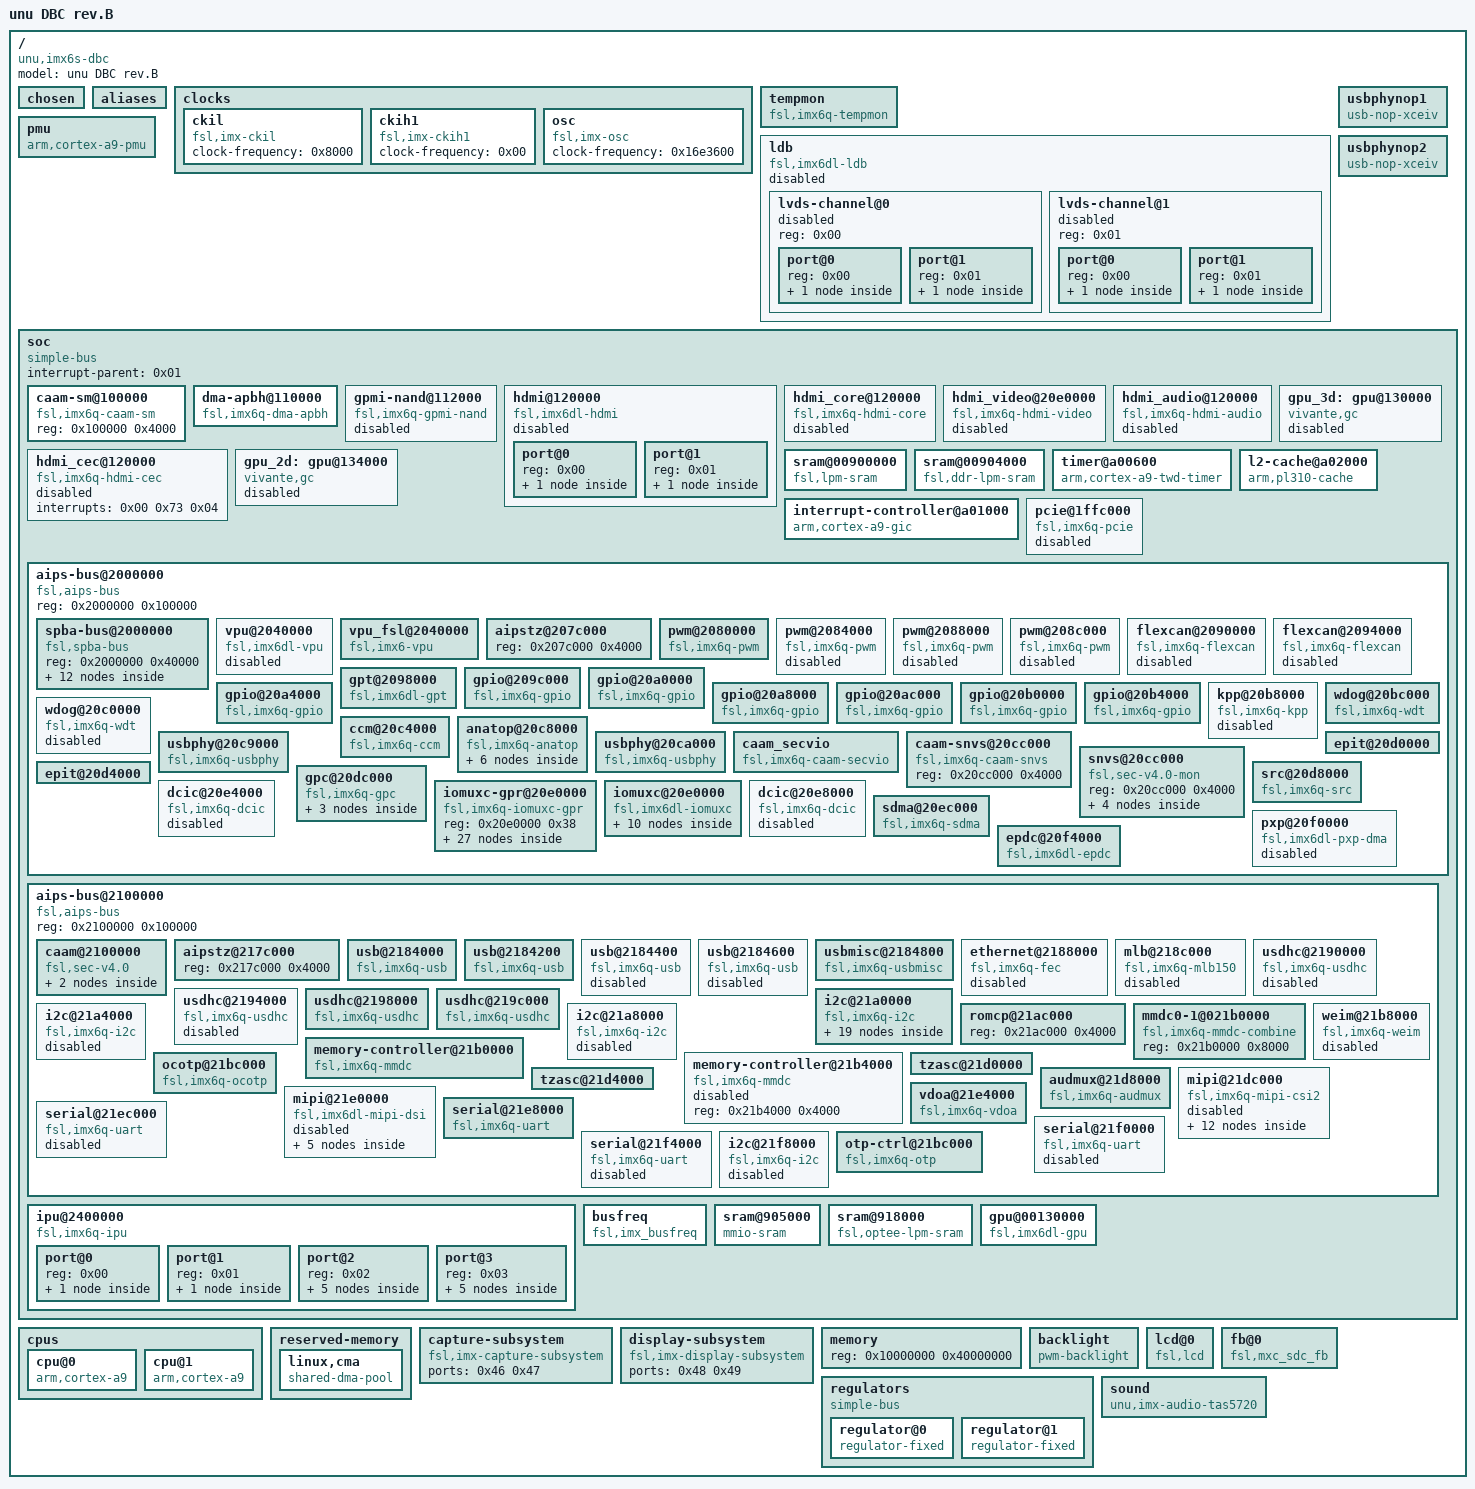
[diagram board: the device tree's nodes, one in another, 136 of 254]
/dts-v1/;

/ {
	#address-cells = <0x01>;
	#size-cells = <0x01>;
	model = "unu DBC rev.B";
	compatible = "unu,imx6s-dbc\0fsl,imx6dl";

	chosen {
	};

	aliases {
		ethernet0 = "/soc/aips-bus@2100000/ethernet@2188000";
		can0 = "/soc/aips-bus@2000000/flexcan@2090000";
		can1 = "/soc/aips-bus@2000000/flexcan@2094000";
		gpio0 = "/soc/aips-bus@2000000/gpio@209c000";
		gpio1 = "/soc/aips-bus@2000000/gpio@20a0000";
		gpio2 = "/soc/aips-bus@2000000/gpio@20a4000";
		gpio3 = "/soc/aips-bus@2000000/gpio@20a8000";
		gpio4 = "/soc/aips-bus@2000000/gpio@20ac000";
		gpio5 = "/soc/aips-bus@2000000/gpio@20b0000";
		gpio6 = "/soc/aips-bus@2000000/gpio@20b4000";
		i2c0 = "/soc/aips-bus@2100000/i2c@21a0000";
		i2c1 = "/soc/aips-bus@2100000/i2c@21a4000";
		i2c2 = "/soc/aips-bus@2100000/i2c@21a8000";
		ipu0 = "/soc/ipu@2400000";
		mmc0 = "/soc/aips-bus@2100000/usdhc@2190000";
		mmc1 = "/soc/aips-bus@2100000/usdhc@2194000";
		mmc2 = "/soc/aips-bus@2100000/usdhc@2198000";
		mmc3 = "/soc/aips-bus@2100000/usdhc@219c000";
		serial0 = "/soc/aips-bus@2000000/spba-bus@2000000/serial@2020000";
		serial1 = "/soc/aips-bus@2100000/serial@21e8000";
		serial2 = "/soc/aips-bus@2100000/serial@21ec000";
		serial3 = "/soc/aips-bus@2100000/serial@21f0000";
		serial4 = "/soc/aips-bus@2100000/serial@21f4000";
		spi0 = "/soc/aips-bus@2000000/spba-bus@2000000/spi@2008000";
		spi1 = "/soc/aips-bus@2000000/spba-bus@2000000/spi@200c000";
		spi2 = "/soc/aips-bus@2000000/spba-bus@2000000/spi@2010000";
		spi3 = "/soc/aips-bus@2000000/spba-bus@2000000/spi@2014000";
		usbphy0 = "/soc/aips-bus@2000000/usbphy@20c9000";
		usbphy1 = "/soc/aips-bus@2000000/usbphy@20ca000";
		i2c3 = "/soc/aips-bus@2100000/i2c@21f8000";
		mxcfb0 = "/fb@0";
	};

	clocks {

		ckil {
			compatible = "fsl,imx-ckil\0fixed-clock";
			#clock-cells = <0x00>;
			clock-frequency = <0x8000>;
		};

		ckih1 {
			compatible = "fsl,imx-ckih1\0fixed-clock";
			#clock-cells = <0x00>;
			clock-frequency = <0x00>;
		};

		osc {
			compatible = "fsl,imx-osc\0fixed-clock";
			#clock-cells = <0x00>;
			clock-frequency = <0x16e3600>;
		};
	};

	tempmon {
		compatible = "fsl,imx6q-tempmon";
		interrupt-parent = <0x01>;
		interrupts = <0x00 0x31 0x04>;
		fsl,tempmon = <0x02>;
		fsl,tempmon-data = <0x03>;
		clocks = <0x04 0xac>;
		#thermal-sensor-cells = <0x00>;
	};

	ldb {
		#address-cells = <0x01>;
		#size-cells = <0x00>;
		compatible = "fsl,imx6dl-ldb\0fsl,imx53-ldb";
		gpr = <0x05>;
		status = "disabled";
		clocks = <0x04 0x87 0x04 0x88 0x04 0x27 0x04 0x28 0x04 0x29 0x04 0xb8 0x04 0xb9 0x04 0x10b 0x04 0x10c 0x04 0x10d 0x04 0x10e>;
		clock-names = "ldb_di0\0ldb_di1\0di0_sel\0di1_sel\0di2_sel\0ldb_di0_div_3_5\0ldb_di1_div_3_5\0ldb_di0_div_7\0ldb_di1_div_7\0ldb_di0_div_sel\0ldb_di1_div_sel";

		lvds-channel@0 {
			#address-cells = <0x01>;
			#size-cells = <0x00>;
			reg = <0x00>;
			status = "disabled";

			port@0 {
				reg = <0x00>;

				endpoint {
					remote-endpoint = <0x06>;
					phandle = <0x3d>;
				};
			};

			port@1 {
				reg = <0x01>;

				endpoint {
					remote-endpoint = <0x07>;
					phandle = <0x41>;
				};
			};
		};

		lvds-channel@1 {
			#address-cells = <0x01>;
			#size-cells = <0x00>;
			reg = <0x01>;
			status = "disabled";

			port@0 {
				reg = <0x00>;

				endpoint {
					remote-endpoint = <0x08>;
					phandle = <0x3e>;
				};
			};

			port@1 {
				reg = <0x01>;

				endpoint {
					remote-endpoint = <0x09>;
					phandle = <0x42>;
				};
			};
		};
	};

	pmu {
		compatible = "arm,cortex-a9-pmu";
		interrupt-parent = <0x01>;
		interrupts = <0x00 0x5e 0x04>;
	};

	usbphynop1 {
		compatible = "usb-nop-xceiv";
		#phy-cells = <0x00>;
		phandle = <0x26>;
	};

	usbphynop2 {
		compatible = "usb-nop-xceiv";
		#phy-cells = <0x00>;
		phandle = <0x27>;
	};

	soc {
		#address-cells = <0x01>;
		#size-cells = <0x01>;
		compatible = "simple-bus";
		interrupt-parent = <0x01>;
		ranges;

		caam-sm@100000 {
			compatible = "fsl,imx6q-caam-sm";
			reg = <0x100000 0x4000>;
		};

		dma-apbh@110000 {
			compatible = "fsl,imx6q-dma-apbh\0fsl,imx28-dma-apbh";
			reg = <0x110000 0x2000>;
			interrupts = <0x00 0x0d 0x04 0x00 0x0d 0x04 0x00 0x0d 0x04 0x00 0x0d 0x04>;
			interrupt-names = "gpmi0\0gpmi1\0gpmi2\0gpmi3";
			#dma-cells = <0x01>;
			dma-channels = <0x04>;
			clocks = <0x04 0x6a>;
			phandle = <0x0a>;
		};

		gpmi-nand@112000 {
			compatible = "fsl,imx6q-gpmi-nand";
			reg = <0x112000 0x2000 0x114000 0x2000>;
			reg-names = "gpmi-nand\0bch";
			interrupts = <0x00 0x0f 0x04>;
			interrupt-names = "bch";
			clocks = <0x04 0x98 0x04 0x99 0x04 0x97 0x04 0x96 0x04 0x95>;
			clock-names = "gpmi_io\0gpmi_apb\0gpmi_bch\0gpmi_bch_apb\0per1_bch";
			dmas = <0x0a 0x00>;
			dma-names = "rx-tx";
			status = "disabled";
		};

		hdmi@120000 {
			#address-cells = <0x01>;
			#size-cells = <0x00>;
			reg = <0x120000 0x9000>;
			interrupts = <0x00 0x73 0x04>;
			gpr = <0x05>;
			clocks = <0x04 0x7b 0x04 0x7c>;
			clock-names = "iahb\0isfr";
			status = "disabled";
			compatible = "fsl,imx6dl-hdmi";

			port@0 {
				reg = <0x00>;

				endpoint {
					remote-endpoint = <0x0b>;
					phandle = <0x3b>;
				};
			};

			port@1 {
				reg = <0x01>;

				endpoint {
					remote-endpoint = <0x0c>;
					phandle = <0x3f>;
				};
			};
		};

		hdmi_core@120000 {
			compatible = "fsl,imx6q-hdmi-core";
			reg = <0x120000 0x9000>;
			clocks = <0x04 0x7c 0x04 0x7b 0x04 0x8a>;
			clock-names = "hdmi_isfr\0hdmi_iahb\0mipi_core";
			status = "disabled";
		};

		hdmi_video@20e0000 {
			compatible = "fsl,imx6q-hdmi-video";
			reg = <0x20e0000 0x1000>;
			reg-names = "hdmi_gpr";
			interrupts = <0x00 0x73 0x04>;
			clocks = <0x04 0x7c 0x04 0x7b 0x04 0x8a>;
			clock-names = "hdmi_isfr\0hdmi_iahb\0mipi_core";
			status = "disabled";
		};

		hdmi_audio@120000 {
			compatible = "fsl,imx6q-hdmi-audio";
			clocks = <0x04 0x7c 0x04 0x7b 0x04 0x8a>;
			clock-names = "hdmi_isfr\0hdmi_iahb\0mipi_core";
			dmas = <0x0d 0x02 0x1a 0x00>;
			dma-names = "tx";
			status = "disabled";
		};

		hdmi_cec@120000 {
			compatible = "fsl,imx6q-hdmi-cec";
			interrupts = <0x00 0x73 0x04>;
			status = "disabled";
		};

		gpu_3d: gpu@130000 {
			compatible = "vivante,gc";
			reg = <0x130000 0x4000>;
			interrupts = <0x00 0x09 0x04>;
			clocks = <0x04 0x1b 0x04 0x7a 0x04 0x4a>;
			clock-names = "bus\0core\0shader";
			power-domains = <0x0e>;
			#cooling-cells = <0x02>;
			status = "disabled";
		};

		gpu_2d: gpu@134000 {
			compatible = "vivante,gc";
			reg = <0x134000 0x4000>;
			interrupts = <0x00 0x0a 0x04>;
			clocks = <0x04 0x1a 0x04 0x79>;
			clock-names = "bus\0core";
			power-domains = <0x0e>;
			#cooling-cells = <0x02>;
			status = "disabled";
		};

		sram@00900000 {
			compatible = "fsl,lpm-sram";
			reg = <0x900000 0x4000>;
			clocks = <0x04 0x8e>;
		};

		sram@00904000 {
			compatible = "fsl,ddr-lpm-sram";
			reg = <0x904000 0x1000>;
			clocks = <0x04 0x8e>;
		};

		timer@a00600 {
			compatible = "arm,cortex-a9-twd-timer";
			reg = <0xa00600 0x20>;
			interrupts = <0x01 0x0d 0xf01>;
			interrupt-parent = <0x0f>;
			clocks = <0x04 0x0f>;
		};

		interrupt-controller@a01000 {
			compatible = "arm,cortex-a9-gic";
			#interrupt-cells = <0x03>;
			interrupt-controller;
			reg = <0xa01000 0x1000 0xa00100 0x100>;
			interrupt-parent = <0x0f>;
			phandle = <0x0f>;
		};

		l2-cache@a02000 {
			compatible = "arm,pl310-cache";
			reg = <0xa02000 0x1000>;
			interrupts = <0x00 0x5c 0x04>;
			cache-unified;
			cache-level = <0x02>;
			arm,tag-latency = <0x04 0x02 0x03>;
			arm,data-latency = <0x04 0x02 0x03>;
			arm,shared-override;
			phandle = <0x43>;
		};

		pcie@1ffc000 {
			compatible = "fsl,imx6q-pcie\0snps,dw-pcie";
			reg = <0x1ffc000 0x4000 0x1f00000 0x80000>;
			reg-names = "dbi\0config";
			#address-cells = <0x03>;
			#size-cells = <0x02>;
			device_type = "pci";
			bus-range = <0x00 0xff>;
			ranges = <0x81000000 0x00 0x00 0x1f80000 0x00 0x10000 0x82000000 0x00 0x1000000 0x1000000 0x00 0xf00000>;
			num-lanes = <0x01>;
			num-viewport = <0x04>;
			interrupts = <0x00 0x78 0x04>;
			interrupt-names = "msi";
			#interrupt-cells = <0x01>;
			interrupt-map-mask = <0x00 0x00 0x00 0x07>;
			interrupt-map = <0x00 0x00 0x00 0x01 0x01 0x00 0x7b 0x04 0x00 0x00 0x00 0x02 0x01 0x00 0x7a 0x04 0x00 0x00 0x00 0x03 0x01 0x00 0x79 0x04 0x00 0x00 0x00 0x04 0x01 0x00 0x78 0x04>;
			clocks = <0x04 0x90 0x04 0xce 0x04 0xbd>;
			clock-names = "pcie\0pcie_bus\0pcie_phy";
			status = "disabled";
		};

		aips-bus@2000000 {
			compatible = "fsl,aips-bus\0simple-bus";
			#address-cells = <0x01>;
			#size-cells = <0x01>;
			reg = <0x2000000 0x100000>;
			ranges;

			spba-bus@2000000 {
				compatible = "fsl,spba-bus\0simple-bus";
				#address-cells = <0x01>;
				#size-cells = <0x01>;
				reg = <0x2000000 0x40000>;
				ranges;

				spdif@2004000 {
					compatible = "fsl,imx35-spdif";
					reg = <0x2004000 0x4000>;
					interrupts = <0x00 0x34 0x04>;
					dmas = <0x0d 0x0e 0x12 0x00 0x0d 0x0f 0x12 0x00>;
					dma-names = "rx\0tx";
					clocks = <0x04 0xf4 0x04 0x03 0x04 0xc5 0x04 0x6b 0x04 0x00 0x04 0x76 0x04 0x3e 0x04 0x8b 0x04 0x00 0x04 0x9c>;
					clock-names = "core\0rxtx0\0rxtx1\0rxtx2\0rxtx3\0rxtx4\0rxtx5\0rxtx6\0rxtx7\0spba";
					status = "disabled";
				};

				spi@2008000 {
					#address-cells = <0x01>;
					#size-cells = <0x00>;
					compatible = "fsl,imx6q-ecspi\0fsl,imx51-ecspi";
					reg = <0x2008000 0x4000>;
					interrupts = <0x00 0x1f 0x04>;
					clocks = <0x04 0x70 0x04 0x70>;
					clock-names = "ipg\0per";
					dmas = <0x0d 0x03 0x07 0x01 0x0d 0x04 0x07 0x02>;
					dma-names = "rx\0tx";
					status = "disabled";
				};

				spi@200c000 {
					#address-cells = <0x01>;
					#size-cells = <0x00>;
					compatible = "fsl,imx6q-ecspi\0fsl,imx51-ecspi";
					reg = <0x200c000 0x4000>;
					interrupts = <0x00 0x20 0x04>;
					clocks = <0x04 0x71 0x04 0x71>;
					clock-names = "ipg\0per";
					dmas = <0x0d 0x05 0x07 0x01 0x0d 0x06 0x07 0x02>;
					dma-names = "rx\0tx";
					status = "disabled";
				};

				spi@2010000 {
					#address-cells = <0x01>;
					#size-cells = <0x00>;
					compatible = "fsl,imx6q-ecspi\0fsl,imx51-ecspi";
					reg = <0x2010000 0x4000>;
					interrupts = <0x00 0x21 0x04>;
					clocks = <0x04 0x72 0x04 0x72>;
					clock-names = "ipg\0per";
					dmas = <0x0d 0x07 0x07 0x01 0x0d 0x08 0x07 0x02>;
					dma-names = "rx\0tx";
					status = "disabled";
				};

				spi@2014000 {
					#address-cells = <0x01>;
					#size-cells = <0x00>;
					compatible = "fsl,imx6q-ecspi\0fsl,imx51-ecspi";
					reg = <0x2014000 0x4000>;
					interrupts = <0x00 0x22 0x04>;
					clocks = <0x04 0x73 0x04 0x73>;
					clock-names = "ipg\0per";
					dmas = <0x0d 0x09 0x07 0x01 0x0d 0x0a 0x07 0x02>;
					dma-names = "rx\0tx";
					status = "disabled";
				};

				serial@2020000 {
					compatible = "fsl,imx6q-uart\0fsl,imx21-uart";
					reg = <0x2020000 0x4000>;
					interrupts = <0x00 0x1a 0x04>;
					clocks = <0x04 0xa0 0x04 0xa1>;
					clock-names = "ipg\0per";
					dmas = <0x0d 0x19 0x04 0x00 0x0d 0x1a 0x04 0x00>;
					dma-names = "rx\0tx";
					status = "okay";
					pinctrl-names = "default";
					pinctrl-0 = <0x10>;
				};

				esai@2024000 {
					#sound-dai-cells = <0x00>;
					compatible = "fsl,imx35-esai";
					reg = <0x2024000 0x4000>;
					interrupts = <0x00 0x33 0x04>;
					clocks = <0x04 0xd0 0x04 0xd1 0x04 0x76 0x04 0xd0 0x04 0x9c>;
					clock-names = "core\0mem\0extal\0fsys\0spba";
					dmas = <0x0d 0x17 0x15 0x00 0x0d 0x18 0x15 0x00>;
					dma-names = "rx\0tx";
					status = "disabled";
				};

				ssi@2028000 {
					#sound-dai-cells = <0x00>;
					compatible = "fsl,imx6q-ssi\0fsl,imx51-ssi";
					reg = <0x2028000 0x4000>;
					interrupts = <0x00 0x2e 0x04>;
					clocks = <0x04 0xb2 0x04 0x9d>;
					clock-names = "ipg\0baud";
					dmas = <0x0d 0x25 0x01 0x00 0x0d 0x26 0x01 0x00>;
					dma-names = "rx\0tx";
					fsl,fifo-depth = <0x0f>;
					status = "okay";
					assigned-clocks = <0x04 0x2d 0x04 0x9d>;
					assigned-clock-parents = <0x04 0xcb>;
					assigned-clock-rates = <0x00 0xbb8000>;
					phandle = <0x4c>;
				};

				ssi@202c000 {
					#sound-dai-cells = <0x00>;
					compatible = "fsl,imx6q-ssi\0fsl,imx51-ssi";
					reg = <0x202c000 0x4000>;
					interrupts = <0x00 0x2f 0x04>;
					clocks = <0x04 0xb3 0x04 0x9e>;
					clock-names = "ipg\0baud";
					dmas = <0x0d 0x29 0x01 0x00 0x0d 0x2a 0x01 0x00>;
					dma-names = "rx\0tx";
					fsl,fifo-depth = <0x0f>;
					status = "disabled";
				};

				ssi@2030000 {
					#sound-dai-cells = <0x00>;
					compatible = "fsl,imx6q-ssi\0fsl,imx51-ssi";
					reg = <0x2030000 0x4000>;
					interrupts = <0x00 0x30 0x04>;
					clocks = <0x04 0xb4 0x04 0x9f>;
					clock-names = "ipg\0baud";
					dmas = <0x0d 0x2d 0x01 0x00 0x0d 0x2e 0x01 0x00>;
					dma-names = "rx\0tx";
					fsl,fifo-depth = <0x0f>;
					status = "disabled";
				};

				asrc@2034000 {
					compatible = "fsl,imx53-asrc";
					reg = <0x2034000 0x4000>;
					interrupts = <0x00 0x32 0x04>;
					clocks = <0x04 0xd2 0x04 0xd3 0x04 0x00 0x04 0x00 0x04 0x00 0x04 0x00 0x04 0x00 0x04 0x00 0x04 0x00 0x04 0x00 0x04 0x00 0x04 0x00 0x04 0x00 0x04 0x00 0x04 0x00 0x04 0x6b 0x04 0x00 0x04 0x00 0x04 0x9c>;
					clock-names = "mem\0ipg\0asrck_0\0asrck_1\0asrck_2\0asrck_3\0asrck_4\0asrck_5\0asrck_6\0asrck_7\0asrck_8\0asrck_9\0asrck_a\0asrck_b\0asrck_c\0asrck_d\0asrck_e\0asrck_f\0spba";
					dmas = <0x0d 0x11 0x17 0x01 0x0d 0x12 0x17 0x01 0x0d 0x13 0x17 0x01 0x0d 0x14 0x17 0x01 0x0d 0x15 0x17 0x01 0x0d 0x16 0x17 0x01>;
					dma-names = "rxa\0rxb\0rxc\0txa\0txb\0txc";
					fsl,asrc-rate = <0xbb80>;
					fsl,asrc-width = <0x10>;
					status = "okay";
				};

				spba@203c000 {
					reg = <0x203c000 0x4000>;
				};
			};

			vpu@2040000 {
				compatible = "fsl,imx6dl-vpu\0cnm,coda960";
				reg = <0x2040000 0x3c000>;
				interrupts = <0x00 0x0c 0x04 0x00 0x03 0x04>;
				interrupt-names = "bit\0jpeg";
				clocks = <0x04 0xa8 0x04 0x8c>;
				clock-names = "per\0ahb";
				power-domains = <0x0e>;
				resets = <0x11 0x01>;
				iram = <0x12>;
				status = "disabled";
			};

			vpu_fsl@2040000 {
				compatible = "fsl,imx6-vpu";
				reg = <0x2040000 0x3c000>;
				reg-names = "vpu_regs";
				interrupts = <0x00 0x03 0x04 0x00 0x0c 0x04>;
				interrupt-names = "vpu_jpu_irq\0vpu_ipi_irq";
				clocks = <0x04 0xa8 0x04 0x8c 0x04 0x8e>;
				clock-names = "vpu_clk\0mmdc_ch0_axi\0ocram";
				iramsize = <0x00>;
				iram = <0x12>;
				resets = <0x11 0x01>;
				power-domains = <0x0e>;
			};

			aipstz@207c000 {
				reg = <0x207c000 0x4000>;
			};

			pwm@2080000 {
				#pwm-cells = <0x02>;
				compatible = "fsl,imx6q-pwm\0fsl,imx27-pwm";
				reg = <0x2080000 0x4000>;
				interrupts = <0x00 0x53 0x04>;
				clocks = <0x04 0x3e 0x04 0x91>;
				clock-names = "ipg\0per";
				status = "okay";
				pinctrl-names = "default";
				pinctrl-0 = <0x13>;
				phandle = <0x4a>;
			};

			pwm@2084000 {
				#pwm-cells = <0x02>;
				compatible = "fsl,imx6q-pwm\0fsl,imx27-pwm";
				reg = <0x2084000 0x4000>;
				interrupts = <0x00 0x54 0x04>;
				clocks = <0x04 0x3e 0x04 0x92>;
				clock-names = "ipg\0per";
				status = "disabled";
			};

			pwm@2088000 {
				#pwm-cells = <0x02>;
				compatible = "fsl,imx6q-pwm\0fsl,imx27-pwm";
				reg = <0x2088000 0x4000>;
				interrupts = <0x00 0x55 0x04>;
				clocks = <0x04 0x3e 0x04 0x93>;
				clock-names = "ipg\0per";
				status = "disabled";
			};

			pwm@208c000 {
				#pwm-cells = <0x02>;
				compatible = "fsl,imx6q-pwm\0fsl,imx27-pwm";
				reg = <0x208c000 0x4000>;
				interrupts = <0x00 0x56 0x04>;
				clocks = <0x04 0x3e 0x04 0x94>;
				clock-names = "ipg\0per";
				status = "disabled";
			};

			flexcan@2090000 {
				compatible = "fsl,imx6q-flexcan";
				reg = <0x2090000 0x4000>;
				interrupts = <0x00 0x6e 0x04>;
				clocks = <0x04 0x6c 0x04 0x6d>;
				clock-names = "ipg\0per";
				fsl,stop-mode = <0x05 0x34 0x1c 0x10 0x11>;
				status = "disabled";
			};

			flexcan@2094000 {
				compatible = "fsl,imx6q-flexcan";
				reg = <0x2094000 0x4000>;
				interrupts = <0x00 0x6f 0x04>;
				clocks = <0x04 0x6e 0x04 0x6f>;
				clock-names = "ipg\0per";
				fsl,stop-mode = <0x05 0x34 0x1d 0x10 0x12>;
				status = "disabled";
			};

			gpt@2098000 {
				compatible = "fsl,imx6dl-gpt";
				reg = <0x2098000 0x4000>;
				interrupts = <0x00 0x37 0x04>;
				clocks = <0x04 0x77 0x04 0x78 0x04 0xed>;
				clock-names = "ipg\0per\0osc_per";
			};

			gpio@209c000 {
				compatible = "fsl,imx6q-gpio\0fsl,imx35-gpio";
				reg = <0x209c000 0x4000>;
				interrupts = <0x00 0x42 0x04 0x00 0x43 0x04>;
				gpio-controller;
				#gpio-cells = <0x02>;
				interrupt-controller;
				#interrupt-cells = <0x02>;
				gpio-ranges = <0x14 0x00 0x83 0x02 0x14 0x02 0x89 0x08 0x14 0x0a 0xbd 0x02 0x14 0x0c 0xc2 0x01 0x14 0x0d 0xc1 0x01 0x14 0x0e 0xc0 0x01 0x14 0x0f 0xbf 0x01 0x14 0x10 0xb9 0x02 0x14 0x12 0xb8 0x01 0x14 0x13 0xbb 0x01 0x14 0x14 0xb7 0x01 0x14 0x15 0xbc 0x01 0x14 0x16 0x7b 0x03 0x14 0x19 0x79 0x01 0x14 0x1a 0x7f 0x01 0x14 0x1b 0x7e 0x01 0x14 0x1c 0x80 0x01 0x14 0x1d 0x82 0x01 0x14 0x1e 0x81 0x01 0x14 0x1f 0x7a 0x01>;
			};

			gpio@20a0000 {
				compatible = "fsl,imx6q-gpio\0fsl,imx35-gpio";
				reg = <0x20a0000 0x4000>;
				interrupts = <0x00 0x44 0x04 0x00 0x45 0x04>;
				gpio-controller;
				#gpio-cells = <0x02>;
				interrupt-controller;
				#interrupt-cells = <0x02>;
				gpio-ranges = <0x14 0x00 0xa1 0x08 0x14 0x08 0xd0 0x08 0x14 0x10 0x4a 0x01 0x14 0x11 0x49 0x01 0x14 0x12 0x48 0x01 0x14 0x13 0x47 0x01 0x14 0x14 0x46 0x01 0x14 0x15 0x45 0x01 0x14 0x16 0x44 0x01 0x14 0x17 0x4f 0x02 0x14 0x19 0x76 0x02 0x14 0x1b 0x75 0x01 0x14 0x1c 0x71 0x04>;
			};

			gpio@20a4000 {
				compatible = "fsl,imx6q-gpio\0fsl,imx35-gpio";
				reg = <0x20a4000 0x4000>;
				interrupts = <0x00 0x46 0x04 0x00 0x47 0x04>;
				gpio-controller;
				#gpio-cells = <0x02>;
				interrupt-controller;
				#interrupt-cells = <0x02>;
				gpio-ranges = <0x14 0x00 0x61 0x02 0x14 0x02 0x69 0x08 0x14 0x0a 0x63 0x06 0x14 0x10 0x51 0x10>;
			};

			gpio@20a8000 {
				compatible = "fsl,imx6q-gpio\0fsl,imx35-gpio";
				reg = <0x20a8000 0x4000>;
				interrupts = <0x00 0x48 0x04 0x00 0x49 0x04>;
				gpio-controller;
				#gpio-cells = <0x02>;
				interrupt-controller;
				#interrupt-cells = <0x02>;
				gpio-ranges = <0x14 0x05 0x88 0x01 0x14 0x06 0x91 0x01 0x14 0x07 0x96 0x01 0x14 0x08 0x92 0x01 0x14 0x09 0x97 0x01 0x14 0x0a 0x93 0x01 0x14 0x0b 0x98 0x01 0x14 0x0c 0x94 0x01 0x14 0x0d 0x99 0x01 0x14 0x0e 0x95 0x01 0x14 0x0f 0x9a 0x01 0x14 0x10 0x27 0x07 0x14 0x17 0x38 0x01 0x14 0x18 0x3d 0x07 0x14 0x1f 0x2e 0x01>;
			};

			gpio@20ac000 {
				compatible = "fsl,imx6q-gpio\0fsl,imx35-gpio";
				reg = <0x20ac000 0x4000>;
				interrupts = <0x00 0x4a 0x04 0x00 0x4b 0x04>;
				gpio-controller;
				#gpio-cells = <0x02>;
				interrupt-controller;
				#interrupt-cells = <0x02>;
				gpio-ranges = <0x14 0x00 0x78 0x01 0x14 0x02 0x4d 0x01 0x14 0x04 0x4c 0x01 0x14 0x05 0x2f 0x09 0x14 0x0e 0x39 0x04 0x14 0x12 0x25 0x01 0x14 0x13 0x24 0x01 0x14 0x14 0x23 0x01 0x14 0x15 0x26 0x01 0x14 0x16 0x1d 0x06 0x14 0x1c 0x13 0x04>;
			};

			gpio@20b0000 {
				compatible = "fsl,imx6q-gpio\0fsl,imx35-gpio";
				reg = <0x20b0000 0x4000>;
				interrupts = <0x00 0x4c 0x04 0x00 0x4d 0x04>;
				gpio-controller;
				#gpio-cells = <0x02>;
				interrupt-controller;
				#interrupt-cells = <0x02>;
				gpio-ranges = <0x14 0x00 0x17 0x06 0x14 0x06 0x4b 0x01 0x14 0x07 0x9c 0x01 0x14 0x08 0x9b 0x01 0x14 0x09 0xaa 0x01 0x14 0x0a 0xa9 0x01 0x14 0x0b 0x9d 0x01 0x14 0x0e 0x9e 0x03 0x14 0x11 0xcc 0x01 0x14 0x12 0xcb 0x01 0x14 0x13 0xb6 0x01 0x14 0x14 0xb1 0x04 0x14 0x18 0xaf 0x01 0x14 0x19 0xab 0x01 0x14 0x1a 0xb5 0x01 0x14 0x1b 0xac 0x03 0x14 0x1e 0xb0 0x01 0x14 0x1f 0x4e 0x01>;
			};

			gpio@20b4000 {
				compatible = "fsl,imx6q-gpio\0fsl,imx35-gpio";
				reg = <0x20b4000 0x4000>;
				interrupts = <0x00 0x4e 0x04 0x00 0x4f 0x04>;
				gpio-controller;
				#gpio-cells = <0x02>;
				interrupt-controller;
				#interrupt-cells = <0x02>;
				gpio-ranges = <0x14 0x00 0xca 0x01 0x14 0x01 0xc9 0x01 0x14 0x02 0xc4 0x01 0x14 0x03 0xc3 0x01 0x14 0x04 0xc5 0x04 0x14 0x08 0xcd 0x01 0x14 0x09 0xcf 0x01 0x14 0x0a 0xce 0x01 0x14 0x0b 0x85 0x03>;
			};

			kpp@20b8000 {
				compatible = "fsl,imx6q-kpp\0fsl,imx21-kpp";
				reg = <0x20b8000 0x4000>;
				interrupts = <0x00 0x52 0x04>;
				clocks = <0x04 0x3e>;
				status = "disabled";
			};

			wdog@20bc000 {
				compatible = "fsl,imx6q-wdt\0fsl,imx21-wdt";
				reg = <0x20bc000 0x4000>;
				interrupts = <0x00 0x50 0x04>;
				clocks = <0x04 0x3e>;
			};

			wdog@20c0000 {
				compatible = "fsl,imx6q-wdt\0fsl,imx21-wdt";
				reg = <0x20c0000 0x4000>;
				interrupts = <0x00 0x51 0x04>;
				clocks = <0x04 0x3e>;
				status = "disabled";
			};

			ccm@20c4000 {
				compatible = "fsl,imx6q-ccm";
				reg = <0x20c4000 0x4000>;
				interrupts = <0x00 0x57 0x04 0x00 0x58 0x04>;
				#clock-cells = <0x01>;
				assigned-clocks = <0x04 0xcb>;
				assigned-clock-rates = <0x2ee00000>;
				phandle = <0x04>;
			};

			anatop@20c8000 {
				compatible = "fsl,imx6q-anatop\0syscon\0simple-mfd";
				reg = <0x20c8000 0x1000>;
				interrupts = <0x00 0x31 0x04 0x00 0x36 0x04 0x00 0x7f 0x04>;
				phandle = <0x02>;

				regulator-1p1 {
					compatible = "fsl,anatop-regulator";
					regulator-name = "vdd1p1";
					regulator-min-microvolt = <0xf4240>;
					regulator-max-microvolt = <0x124f80>;
					regulator-always-on;
					anatop-reg-offset = <0x110>;
					anatop-vol-bit-shift = <0x08>;
					anatop-vol-bit-width = <0x05>;
					anatop-min-bit-val = <0x04>;
					anatop-min-voltage = "\0\f5";
					anatop-max-voltage = <0x14fb18>;
					anatop-enable-bit = <0x00>;
				};

				regulator-3p0 {
					compatible = "fsl,anatop-regulator";
					regulator-name = "vdd3p0";
					regulator-min-microvolt = <0x2ab980>;
					regulator-max-microvolt = <0x3010b0>;
					regulator-always-on;
					anatop-reg-offset = <0x120>;
					anatop-vol-bit-shift = <0x08>;
					anatop-vol-bit-width = <0x05>;
					anatop-min-bit-val = <0x00>;
					anatop-min-voltage = <0x280de8>;
					anatop-max-voltage = <0x33e140>;
					anatop-enable-bit = <0x00>;
				};

				regulator-2p5 {
					compatible = "fsl,anatop-regulator";
					regulator-name = "vdd2p5";
					regulator-min-microvolt = <0x225510>;
					regulator-max-microvolt = <0x29f630>;
					regulator-always-on;
					anatop-reg-offset = <0x130>;
					anatop-vol-bit-shift = <0x08>;
					anatop-vol-bit-width = <0x05>;
					anatop-min-bit-val = <0x00>;
					anatop-min-voltage = <0x200b20>;
					anatop-max-voltage = <0x2bde78>;
					anatop-enable-bit = <0x00>;
				};

				regulator-vddcore {
					compatible = "fsl,anatop-regulator";
					regulator-name = "vddarm";
					regulator-min-microvolt = <0xb1008>;
					regulator-max-microvolt = <0x162010>;
					regulator-always-on;
					anatop-reg-offset = <0x140>;
					anatop-vol-bit-shift = <0x00>;
					anatop-vol-bit-width = <0x05>;
					anatop-delay-reg-offset = <0x170>;
					anatop-delay-bit-shift = <0x18>;
					anatop-delay-bit-width = <0x02>;
					anatop-min-bit-val = <0x01>;
					anatop-min-voltage = <0xb1008>;
					anatop-max-voltage = <0x162010>;
					regulator-allow-bypass;
					phandle = <0x44>;
				};

				regulator-vddpu {
					compatible = "fsl,anatop-regulator";
					regulator-name = "vddpu";
					regulator-min-microvolt = <0xb1008>;
					regulator-max-microvolt = <0x162010>;
					regulator-enable-ramp-delay = <0x96>;
					anatop-reg-offset = <0x140>;
					anatop-vol-bit-shift = <0x09>;
					anatop-vol-bit-width = <0x05>;
					anatop-delay-reg-offset = <0x170>;
					anatop-delay-bit-shift = <0x1a>;
					anatop-delay-bit-width = <0x02>;
					anatop-min-bit-val = <0x01>;
					anatop-min-voltage = <0xb1008>;
					anatop-max-voltage = <0x162010>;
					regulator-allow-bypass;
					phandle = <0x16>;
				};

				regulator-vddsoc {
					compatible = "fsl,anatop-regulator";
					regulator-name = "vddsoc";
					regulator-min-microvolt = <0xb1008>;
					regulator-max-microvolt = <0x162010>;
					regulator-always-on;
					anatop-reg-offset = <0x140>;
					anatop-vol-bit-shift = <0x12>;
					anatop-vol-bit-width = <0x05>;
					anatop-delay-reg-offset = <0x170>;
					anatop-delay-bit-shift = <0x1c>;
					anatop-delay-bit-width = <0x02>;
					anatop-min-bit-val = <0x01>;
					anatop-min-voltage = <0xb1008>;
					anatop-max-voltage = <0x162010>;
					regulator-allow-bypass;
					phandle = <0x45>;
				};
			};

			usbphy@20c9000 {
				compatible = "fsl,imx6q-usbphy\0fsl,imx23-usbphy";
				reg = <0x20c9000 0x1000>;
				interrupts = <0x00 0x2c 0x04>;
				clocks = <0x04 0xb6>;
				fsl,anatop = <0x02>;
				phandle = <0x23>;
			};

			usbphy@20ca000 {
				compatible = "fsl,imx6q-usbphy\0fsl,imx23-usbphy";
				reg = <0x20ca000 0x1000>;
				interrupts = <0x00 0x2d 0x04>;
				clocks = <0x04 0xb7>;
				fsl,anatop = <0x02>;
				phandle = <0x25>;
			};

			caam_secvio {
				compatible = "fsl,imx6q-caam-secvio";
				interrupts = <0x00 0x14 0x04>;
				jtag-tamper = "disabled";
				watchdog-tamper = "enabled";
				internal-boot-tamper = "enabled";
				external-pin-tamper = "disabled";
			};

			caam-snvs@20cc000 {
				compatible = "fsl,imx6q-caam-snvs";
				reg = <0x20cc000 0x4000>;
			};

			snvs@20cc000 {
				compatible = "fsl,sec-v4.0-mon\0syscon\0simple-mfd";
				reg = <0x20cc000 0x4000>;
				phandle = <0x15>;

				snvs-rtc-lp {
					compatible = "fsl,sec-v4.0-mon-rtc-lp";
					regmap = <0x15>;
					offset = <0x34>;
					interrupts = <0x00 0x13 0x04 0x00 0x14 0x04>;
				};

				snvs-poweroff {
					compatible = "syscon-poweroff";
					regmap = <0x15>;
					offset = <0x38>;
					value = <0x60>;
					mask = <0x60>;
					status = "disabled";
				};

				snvs-powerkey {
					compatible = "fsl,sec-v4.0-pwrkey";
					regmap = <0x15>;
					interrupts = <0x00 0x04 0x04>;
					linux,keycode = <0x74>;
					wakeup-source;
					status = "disabled";
				};

				snvs-lpgpr {
					compatible = "fsl,imx6q-snvs-lpgpr";
				};
			};

			epit@20d0000 {
				reg = <0x20d0000 0x4000>;
				interrupts = <0x00 0x38 0x04>;
			};

			epit@20d4000 {
				reg = <0x20d4000 0x4000>;
				interrupts = <0x00 0x39 0x04>;
			};

			src@20d8000 {
				compatible = "fsl,imx6q-src\0fsl,imx51-src";
				reg = <0x20d8000 0x4000>;
				interrupts = <0x00 0x5b 0x04 0x00 0x60 0x04>;
				#reset-cells = <0x01>;
				phandle = <0x11>;
			};

			gpc@20dc000 {
				compatible = "fsl,imx6q-gpc";
				reg = <0x20dc000 0x4000>;
				interrupt-controller;
				#interrupt-cells = <0x03>;
				interrupts = <0x00 0x59 0x04 0x00 0x5a 0x04>;
				interrupt-parent = <0x0f>;
				clocks = <0x04 0x3e>;
				clock-names = "ipg";
				phandle = <0x01>;

				pgc {
					#address-cells = <0x01>;
					#size-cells = <0x00>;

					power-domain@0 {
						reg = <0x00>;
						#power-domain-cells = <0x00>;
					};

					power-domain@1 {
						reg = <0x01>;
						#power-domain-cells = <0x00>;
						power-supply = <0x16>;
						clocks = <0x04 0x7a 0x04 0x4a 0x04 0x79 0x04 0x1a 0x04 0x8f 0x04 0xa8>;
						phandle = <0x0e>;
					};
				};
			};

			iomuxc-gpr@20e0000 {
				compatible = "fsl,imx6q-iomuxc-gpr\0syscon\0simple-mfd";
				reg = <0x20e0000 0x38>;
				phandle = <0x05>;

				mux-controller {
					compatible = "mmio-mux";
					#mux-control-cells = <0x01>;
					mux-reg-masks = <0x34 0x07 0x34 0x38 0x0c 0x0c 0x0c 0xc0 0x0c 0x300 0x28 0x03 0x28 0x0c>;
					phandle = <0x17>;
				};

				ipu1_csi0_mux {
					compatible = "video-mux";
					mux-controls = <0x17 0x00>;
					#address-cells = <0x01>;
					#size-cells = <0x00>;

					port@0 {
						reg = <0x00>;

						endpoint {
							remote-endpoint = <0x18>;
							phandle = <0x2e>;
						};
					};

					port@1 {
						reg = <0x01>;

						endpoint {
							remote-endpoint = <0x19>;
							phandle = <0x30>;
						};
					};

					port@2 {
						reg = <0x02>;

						endpoint {
							remote-endpoint = <0x1a>;
							phandle = <0x32>;
						};
					};

					port@3 {
						reg = <0x03>;

						endpoint {
							remote-endpoint = <0x1b>;
							phandle = <0x34>;
						};
					};

					port@4 {
						reg = <0x04>;

						endpoint {
						};
					};

					port@5 {
						reg = <0x05>;

						endpoint {
							remote-endpoint = <0x1c>;
							phandle = <0x39>;
						};
					};
				};

				ipu1_csi1_mux {
					compatible = "video-mux";
					mux-controls = <0x17 0x01>;
					#address-cells = <0x01>;
					#size-cells = <0x00>;

					port@0 {
						reg = <0x00>;

						endpoint {
							remote-endpoint = <0x1d>;
							phandle = <0x2f>;
						};
					};

					port@1 {
						reg = <0x01>;

						endpoint {
							remote-endpoint = <0x1e>;
							phandle = <0x31>;
						};
					};

					port@2 {
						reg = <0x02>;

						endpoint {
							remote-endpoint = <0x1f>;
							phandle = <0x33>;
						};
					};

					port@3 {
						reg = <0x03>;

						endpoint {
							remote-endpoint = <0x20>;
							phandle = <0x35>;
						};
					};

					port@4 {
						reg = <0x04>;

						endpoint {
						};
					};

					port@5 {
						reg = <0x05>;

						endpoint {
							remote-endpoint = <0x21>;
							phandle = <0x3a>;
						};
					};
				};
			};

			iomuxc@20e0000 {
				compatible = "fsl,imx6dl-iomuxc";
				reg = <0x20e0000 0x4000>;
				pinctrl-names = "default";
				pinctrl-0 = <0x22>;
				phandle = <0x14>;

				imx6q-sabrelite {

					hoggrp {
						fsl,pins = <0x20c 0x5dc 0x00 0x00 0x00 0x130b0 0x210 0x5e0 0x00 0x05 0x00 0x4001b8b1>;
						phandle = <0x22>;
					};

					audmuxgrp {
						fsl,pins = <0x80 0x394 0x00 0x04 0x00 0x130b0 0x74 0x388 0x00 0x04 0x00 0x130b0 0x78 0x38c 0x00 0x04 0x00 0x110b0 0x7c 0x390 0x00 0x04 0x00 0x130b0>;
						phandle = <0x2d>;
					};

					i2c1grp {
						fsl,pins = <0x88 0x39c 0x868 0x04 0x00 0x4001b8b1 0x84 0x398 0x86c 0x04 0x00 0x4001b8b1>;
						phandle = <0x2a>;
					};

					lcdgrp {
						fsl,pins = <0x9c 0x3b0 0x00 0x00 0x00 0xa1 0xa0 0x3b4 0x00 0x00 0x00 0xa1 0xa4 0x3b8 0x00 0x00 0x00 0xa1 0xa8 0x3bc 0x00 0x00 0x00 0xa1 0xb0 0x3c4 0x00 0x00 0x00 0xa1 0xb4 0x3c8 0x00 0x00 0x00 0xa1 0xe0 0x3f4 0x00 0x00 0x00 0xa1 0xf4 0x408 0x00 0x00 0x00 0xa1 0xf8 0x40c 0x00 0x00 0x00 0xa1 0xfc 0x410 0x00 0x00 0x00 0xa1 0x100 0x414 0x00 0x00 0x00 0xa1 0x104 0x418 0x00 0x00 0x00 0xa1 0x108 0x41c 0x00 0x00 0x00 0xa1 0x10c 0x420 0x00 0x00 0x00 0xa1 0xb8 0x3cc 0x00 0x00 0x00 0xa1 0xbc 0x3d0 0x00 0x00 0x00 0xa1 0xc0 0x3d4 0x00 0x00 0x00 0xa1 0xc4 0x3d8 0x00 0x00 0x00 0xa1 0xc8 0x3dc 0x00 0x00 0x00 0xa1 0xcc 0x3e0 0x00 0x00 0x00 0xa1 0xd0 0x3e4 0x00 0x00 0x00 0xa1 0xd4 0x3e8 0x00 0x00 0x00 0xa1 0xd8 0x3ec 0x00 0x00 0x00 0xa1 0xdc 0x3f0 0x00 0x00 0x00 0xa1 0xe4 0x3f8 0x00 0x00 0x00 0xa1 0xe8 0x3fc 0x00 0x00 0x00 0xa1 0xec 0x400 0x00 0x00 0x00 0xa1 0xf0 0x404 0x00 0x00 0x00 0xa1>;
						phandle = <0x4b>;
					};

					pwm1grp {
						fsl,pins = <0x2f0 0x6d8 0x00 0x03 0x00 0x1b0b1>;
						phandle = <0x13>;
					};

					uart1grp {
						fsl,pins = <0x4c 0x360 0x00 0x03 0x00 0x1b0b1 0x50 0x364 0x8fc 0x03 0x01 0x1b0b1>;
						phandle = <0x10>;
					};

					uart2grp {
						fsl,pins = <0x238 0x608 0x00 0x04 0x00 0x1b0b1 0x23c 0x60c 0x904 0x04 0x03 0x1b0b1>;
						phandle = <0x38>;
					};

					usdhc3grp {
						fsl,pins = <0x310 0x6f8 0x00 0x00 0x00 0x17059 0x30c 0x6f4 0x934 0x00 0x01 0x10059 0x314 0x6fc 0x00 0x00 0x00 0x17059 0x318 0x700 0x00 0x00 0x00 0x17059 0x31c 0x704 0x00 0x00 0x00 0x17059 0x320 0x708 0x00 0x00 0x00 0x17059>;
						phandle = <0x28>;
					};

					usdhc4grp {
						fsl,pins = <0x33c 0x724 0x00 0x00 0x00 0x17059 0x338 0x720 0x938 0x00 0x01 0x10059 0x340 0x728 0x00 0x01 0x00 0x17059 0x344 0x72c 0x00 0x01 0x00 0x17059 0x348 0x730 0x00 0x01 0x00 0x17059 0x34c 0x734 0x00 0x01 0x00 0x17059 0x350 0x738 0x00 0x01 0x00 0x17059 0x354 0x73c 0x00 0x01 0x00 0x17059 0x358 0x740 0x00 0x01 0x00 0x17059 0x35c 0x744 0x00 0x01 0x00 0x17059>;
						phandle = <0x29>;
					};
				};
			};

			dcic@20e4000 {
				compatible = "fsl,imx6q-dcic";
				reg = <0x20e4000 0x4000>;
				interrupts = <0x00 0x7c 0x04>;
				clocks = <0x04 0x108 0x04 0x108>;
				clock-names = "dcic\0disp-axi";
				gpr = <0x05>;
				status = "disabled";
			};

			dcic@20e8000 {
				compatible = "fsl,imx6q-dcic";
				reg = <0x20e8000 0x4000>;
				interrupts = <0x00 0x7d 0x04>;
				clocks = <0x04 0x108 0x04 0x109>;
				clock-names = "dcic\0disp-axi";
				gpr = <0x05>;
				status = "disabled";
			};

			sdma@20ec000 {
				compatible = "fsl,imx6q-sdma\0fsl,imx35-sdma";
				reg = <0x20ec000 0x4000>;
				interrupts = <0x00 0x02 0x04>;
				clocks = <0x04 0x3e 0x04 0x9b>;
				clock-names = "ipg\0ahb";
				#dma-cells = <0x03>;
				fsl,sdma-ram-script-name = "imx/sdma/sdma-imx6q.bin";
				phandle = <0x0d>;
			};

			pxp@20f0000 {
				compatible = "fsl,imx6dl-pxp-dma";
				reg = <0x20f0000 0x4000>;
				interrupts = <0x00 0x62 0x04>;
				clocks = <0x04 0x85 0x04 0x00>;
				clock-names = "pxp-axi\0disp-axi";
				status = "disabled";
			};

			epdc@20f4000 {
				compatible = "fsl,imx6dl-epdc";
				reg = <0x20f4000 0x4000>;
				interrupts = <0x00 0x61 0x04>;
				clocks = <0x04 0x85 0x04 0x89>;
				clock-names = "epdc_axi\0epdc_pix";
			};
		};

		aips-bus@2100000 {
			compatible = "fsl,aips-bus\0simple-bus";
			#address-cells = <0x01>;
			#size-cells = <0x01>;
			reg = <0x2100000 0x100000>;
			ranges;

			caam@2100000 {
				compatible = "fsl,sec-v4.0";
				#address-cells = <0x01>;
				#size-cells = <0x01>;
				reg = <0x2100000 0x10000>;
				ranges = <0x00 0x2100000 0x10000>;
				clocks = <0x04 0xf1 0x04 0xf2 0x04 0xf3 0x04 0xc4>;
				clock-names = "mem\0aclk\0ipg\0emi_slow";

				jr0@1000 {
					compatible = "fsl,sec-v4.0-job-ring";
					reg = <0x1000 0x1000>;
					interrupts = <0x00 0x69 0x04>;
				};

				jr1@2000 {
					compatible = "fsl,sec-v4.0-job-ring";
					reg = <0x2000 0x1000>;
					interrupts = <0x00 0x6a 0x04>;
				};
			};

			aipstz@217c000 {
				reg = <0x217c000 0x4000>;
			};

			usb@2184000 {
				compatible = "fsl,imx6q-usb\0fsl,imx27-usb";
				reg = <0x2184000 0x200>;
				interrupts = <0x00 0x2b 0x04>;
				clocks = <0x04 0xa2>;
				fsl,usbphy = <0x23>;
				fsl,usbmisc = <0x24 0x00>;
				ahb-burst-config = <0x00>;
				tx-burst-size-dword = <0x10>;
				rx-burst-size-dword = <0x10>;
				status = "okay";
				disable-over-current;
				dr_mode = "host";
			};

			usb@2184200 {
				compatible = "fsl,imx6q-usb\0fsl,imx27-usb";
				reg = <0x2184200 0x200>;
				interrupts = <0x00 0x28 0x04>;
				clocks = <0x04 0xa2>;
				fsl,usbphy = <0x25>;
				fsl,usbmisc = <0x24 0x01>;
				dr_mode = "host";
				ahb-burst-config = <0x00>;
				tx-burst-size-dword = <0x10>;
				rx-burst-size-dword = <0x10>;
				status = "okay";
			};

			usb@2184400 {
				compatible = "fsl,imx6q-usb\0fsl,imx27-usb";
				reg = <0x2184400 0x200>;
				interrupts = <0x00 0x29 0x04>;
				clocks = <0x04 0xa2>;
				fsl,usbphy = <0x26>;
				phy_type = "hsic";
				fsl,usbmisc = <0x24 0x02>;
				dr_mode = "host";
				ahb-burst-config = <0x00>;
				tx-burst-size-dword = <0x10>;
				rx-burst-size-dword = <0x10>;
				status = "disabled";
			};

			usb@2184600 {
				compatible = "fsl,imx6q-usb\0fsl,imx27-usb";
				reg = <0x2184600 0x200>;
				interrupts = <0x00 0x2a 0x04>;
				clocks = <0x04 0xa2>;
				fsl,usbphy = <0x27>;
				phy_type = "hsic";
				fsl,usbmisc = <0x24 0x03>;
				dr_mode = "host";
				ahb-burst-config = <0x00>;
				tx-burst-size-dword = <0x10>;
				rx-burst-size-dword = <0x10>;
				status = "disabled";
			};

			usbmisc@2184800 {
				#index-cells = <0x01>;
				compatible = "fsl,imx6q-usbmisc";
				reg = <0x2184800 0x200>;
				clocks = <0x04 0xa2>;
				phandle = <0x24>;
			};

			ethernet@2188000 {
				compatible = "fsl,imx6q-fec";
				reg = <0x2188000 0x4000>;
				interrupt-names = "int0\0pps";
				interrupts-extended = <0x01 0x00 0x76 0x04 0x01 0x00 0x77 0x04>;
				clocks = <0x04 0x75 0x04 0x75 0x04 0xbe>;
				clock-names = "ipg\0ahb\0ptp";
				stop-mode = <0x05 0x34 0x1b>;
				fsl,wakeup_irq = <0x00>;
				status = "disabled";
			};

			mlb@218c000 {
				compatible = "fsl,imx6q-mlb150";
				reg = <0x218c000 0x4000>;
				interrupts = <0x00 0x35 0x04 0x00 0x75 0x04 0x00 0x7e 0x04>;
				clocks = <0x04 0x8b>;
				clock-names = "mlb";
				iram = <0x12>;
				status = "disabled";
			};

			usdhc@2190000 {
				compatible = "fsl,imx6q-usdhc";
				reg = <0x2190000 0x4000>;
				interrupts = <0x00 0x16 0x04>;
				clocks = <0x04 0xa3 0x04 0xa3 0x04 0xa3>;
				clock-names = "ipg\0ahb\0per";
				bus-width = <0x04>;
				status = "disabled";
			};

			usdhc@2194000 {
				compatible = "fsl,imx6q-usdhc";
				reg = <0x2194000 0x4000>;
				interrupts = <0x00 0x17 0x04>;
				clocks = <0x04 0xa4 0x04 0xa4 0x04 0xa4>;
				clock-names = "ipg\0ahb\0per";
				bus-width = <0x04>;
				status = "disabled";
			};

			usdhc@2198000 {
				compatible = "fsl,imx6q-usdhc";
				reg = <0x2198000 0x4000>;
				interrupts = <0x00 0x18 0x04>;
				clocks = <0x04 0xa5 0x04 0xa5 0x04 0xa5>;
				clock-names = "ipg\0ahb\0per";
				bus-width = <0x04>;
				status = "okay";
				pinctrl-names = "default";
				pinctrl-0 = <0x28>;
			};

			usdhc@219c000 {
				compatible = "fsl,imx6q-usdhc";
				reg = <0x219c000 0x4000>;
				interrupts = <0x00 0x19 0x04>;
				clocks = <0x04 0xa6 0x04 0xa6 0x04 0xa6>;
				clock-names = "ipg\0ahb\0per";
				bus-width = <0x08>;
				status = "okay";
				pinctrl-names = "default";
				pinctrl-0 = <0x29>;
			};

			i2c@21a0000 {
				#address-cells = <0x01>;
				#size-cells = <0x00>;
				compatible = "fsl,imx6q-i2c\0fsl,imx21-i2c";
				reg = <0x21a0000 0x4000>;
				interrupts = <0x00 0x24 0x04>;
				clocks = <0x04 0x7d>;
				status = "okay";
				clock-frequency = <0x186a0>;
				pinctrl-names = "default";
				pinctrl-0 = <0x2a>;

				opt3001@44 {
					compatible = "ti,opt3001";
					reg = <0x44>;
				};

				tas5720@6c {
					status = "okay";
					compatible = "ti,tas5720";
					reg = <0x6c>;
					dvdd-supply = <0x2b>;
					pvdd-supply = <0x2c>;
					phandle = <0x4d>;
				};

				pfuze100@8 {
					compatible = "fsl,pfuze100";
					reg = <0x08>;

					regulators {

						sw1ab {
							regulator-min-microvolt = <0x493e0>;
							regulator-max-microvolt = <0x1c9c38>;
							regulator-boot-on;
							regulator-always-on;
							regulator-ramp-delay = <0x186a>;
						};

						sw1c {
							regulator-min-microvolt = <0x493e0>;
							regulator-max-microvolt = <0x1c9c38>;
							regulator-boot-on;
							regulator-always-on;
							regulator-ramp-delay = <0x186a>;
						};

						sw2 {
							regulator-min-microvolt = "\0\f5";
							regulator-max-microvolt = <0x325aa0>;
							regulator-boot-on;
							regulator-always-on;
							regulator-ramp-delay = <0x186a>;
						};

						sw3a {
							regulator-min-microvolt = <0x61a80>;
							regulator-max-microvolt = <0x16e360>;
							regulator-boot-on;
							regulator-always-on;
						};

						sw3b {
							regulator-min-microvolt = <0x61a80>;
							regulator-max-microvolt = <0x1e22d8>;
							regulator-boot-on;
							regulator-always-on;
						};

						sw4 {
							regulator-min-microvolt = "\0\f5";
							regulator-max-microvolt = <0x325aa0>;
						};

						swbst {
							regulator-min-microvolt = <0x4c4b40>;
							regulator-max-microvolt = <0x4e9530>;
						};

						vsnvs {
							regulator-min-microvolt = <0xf4240>;
							regulator-max-microvolt = <0x2dc6c0>;
							regulator-boot-on;
							regulator-always-on;
						};

						vrefddr {
							regulator-boot-on;
							regulator-always-on;
						};

						vgen1 {
							regulator-min-microvolt = "\0\f5";
							regulator-max-microvolt = <0x17a6b0>;
						};

						vgen2 {
							regulator-min-microvolt = "\0\f5";
							regulator-max-microvolt = <0x17a6b0>;
						};

						vgen3 {
							regulator-min-microvolt = <0x1b7740>;
							regulator-max-microvolt = <0x325aa0>;
						};

						vgen4 {
							regulator-min-microvolt = <0x1b7740>;
							regulator-max-microvolt = <0x325aa0>;
							regulator-always-on;
						};

						vgen5 {
							regulator-min-microvolt = <0x1b7740>;
							regulator-max-microvolt = <0x325aa0>;
							regulator-always-on;
						};

						vgen6 {
							regulator-min-microvolt = <0x1b7740>;
							regulator-max-microvolt = <0x325aa0>;
							regulator-always-on;
						};
					};
				};
			};

			i2c@21a4000 {
				#address-cells = <0x01>;
				#size-cells = <0x00>;
				compatible = "fsl,imx6q-i2c\0fsl,imx21-i2c";
				reg = <0x21a4000 0x4000>;
				interrupts = <0x00 0x25 0x04>;
				clocks = <0x04 0x7e>;
				status = "disabled";
			};

			i2c@21a8000 {
				#address-cells = <0x01>;
				#size-cells = <0x00>;
				compatible = "fsl,imx6q-i2c\0fsl,imx21-i2c";
				reg = <0x21a8000 0x4000>;
				interrupts = <0x00 0x26 0x04>;
				clocks = <0x04 0x7f>;
				status = "disabled";
			};

			romcp@21ac000 {
				reg = <0x21ac000 0x4000>;
			};

			mmdc0-1@021b0000 {
				compatible = "fsl,imx6q-mmdc-combine";
				reg = <0x21b0000 0x8000>;
			};

			memory-controller@21b0000 {
				compatible = "fsl,imx6q-mmdc";
				reg = <0x21b0000 0x4000>;
				clocks = <0x04 0x107>;
			};

			memory-controller@21b4000 {
				compatible = "fsl,imx6q-mmdc";
				reg = <0x21b4000 0x4000>;
				status = "disabled";
			};

			weim@21b8000 {
				#address-cells = <0x02>;
				#size-cells = <0x01>;
				compatible = "fsl,imx6q-weim";
				reg = <0x21b8000 0x4000>;
				interrupts = <0x00 0x0e 0x04>;
				clocks = <0x04 0xc4>;
				fsl,weim-cs-gpr = <0x05>;
				status = "disabled";
			};

			ocotp@21bc000 {
				compatible = "fsl,imx6q-ocotp\0syscon";
				reg = <0x21bc000 0x4000>;
				clocks = <0x04 0x80>;
				phandle = <0x03>;
			};

			tzasc@21d0000 {
				reg = <0x21d0000 0x4000>;
				interrupts = <0x00 0x6c 0x04>;
			};

			tzasc@21d4000 {
				reg = <0x21d4000 0x4000>;
				interrupts = <0x00 0x6d 0x04>;
			};

			audmux@21d8000 {
				compatible = "fsl,imx6q-audmux\0fsl,imx31-audmux";
				reg = <0x21d8000 0x4000>;
				status = "okay";
				pinctrl-names = "default";
				pinctrl-0 = <0x2d>;
			};

			mipi@21dc000 {
				compatible = "fsl,imx6q-mipi-csi2";
				reg = <0x21dc000 0x4000>;
				#address-cells = <0x01>;
				#size-cells = <0x00>;
				interrupts = <0x00 0x64 0x04 0x00 0x65 0x04>;
				clocks = <0x04 0x8a 0x04 0xee 0x04 0x35>;
				clock-names = "dphy_clk\0cfg_clk\0pixel_clk";
				status = "disabled";

				port@1 {
					reg = <0x01>;
					#address-cells = <0x01>;
					#size-cells = <0x00>;

					endpoint@0 {
						reg = <0x00>;
						remote-endpoint = <0x2e>;
						phandle = <0x18>;
					};

					endpoint@1 {
						reg = <0x01>;
						remote-endpoint = <0x2f>;
						phandle = <0x1d>;
					};
				};

				port@2 {
					reg = <0x02>;
					#address-cells = <0x01>;
					#size-cells = <0x00>;

					endpoint@0 {
						reg = <0x00>;
						remote-endpoint = <0x30>;
						phandle = <0x19>;
					};

					endpoint@1 {
						reg = <0x01>;
						remote-endpoint = <0x31>;
						phandle = <0x1e>;
					};
				};

				port@3 {
					reg = <0x03>;
					#address-cells = <0x01>;
					#size-cells = <0x00>;

					endpoint@0 {
						reg = <0x00>;
						remote-endpoint = <0x32>;
						phandle = <0x1a>;
					};

					endpoint@1 {
						reg = <0x01>;
						remote-endpoint = <0x33>;
						phandle = <0x1f>;
					};
				};

				port@4 {
					reg = <0x04>;
					#address-cells = <0x01>;
					#size-cells = <0x00>;

					endpoint@0 {
						reg = <0x00>;
						remote-endpoint = <0x34>;
						phandle = <0x1b>;
					};

					endpoint@1 {
						reg = <0x01>;
						remote-endpoint = <0x35>;
						phandle = <0x20>;
					};
				};
			};

			mipi@21e0000 {
				reg = <0x21e0000 0x4000>;
				status = "disabled";
				compatible = "fsl,imx6dl-mipi-dsi";
				interrupts = <0x00 0x66 0x04>;
				gpr = <0x05>;
				clocks = <0x04 0x8a 0x04 0xee>;
				clock-names = "mipi_pllref_clk\0mipi_cfg_clk";

				ports {
					#address-cells = <0x01>;
					#size-cells = <0x00>;

					port@0 {
						reg = <0x00>;

						endpoint {
							remote-endpoint = <0x36>;
							phandle = <0x3c>;
						};
					};

					port@1 {
						reg = <0x01>;

						endpoint {
							remote-endpoint = <0x37>;
							phandle = <0x40>;
						};
					};
				};
			};

			vdoa@21e4000 {
				compatible = "fsl,imx6q-vdoa";
				reg = <0x21e4000 0x4000>;
				interrupts = <0x00 0x12 0x04>;
				clocks = <0x04 0xca>;
				iram = <0x12>;
			};

			serial@21e8000 {
				compatible = "fsl,imx6q-uart\0fsl,imx21-uart";
				reg = <0x21e8000 0x4000>;
				interrupts = <0x00 0x1b 0x04>;
				clocks = <0x04 0xa0 0x04 0xa1>;
				clock-names = "ipg\0per";
				dmas = <0x0d 0x1b 0x04 0x00 0x0d 0x1c 0x04 0x00>;
				dma-names = "rx\0tx";
				status = "okay";
				pinctrl-names = "default";
				pinctrl-0 = <0x38>;
			};

			serial@21ec000 {
				compatible = "fsl,imx6q-uart\0fsl,imx21-uart";
				reg = <0x21ec000 0x4000>;
				interrupts = <0x00 0x1c 0x04>;
				clocks = <0x04 0xa0 0x04 0xa1>;
				clock-names = "ipg\0per";
				dmas = <0x0d 0x1d 0x04 0x00 0x0d 0x1e 0x04 0x00>;
				dma-names = "rx\0tx";
				status = "disabled";
			};

			serial@21f0000 {
				compatible = "fsl,imx6q-uart\0fsl,imx21-uart";
				reg = <0x21f0000 0x4000>;
				interrupts = <0x00 0x1d 0x04>;
				clocks = <0x04 0xa0 0x04 0xa1>;
				clock-names = "ipg\0per";
				dmas = <0x0d 0x1f 0x04 0x00 0x0d 0x20 0x04 0x00>;
				dma-names = "rx\0tx";
				status = "disabled";
			};

			serial@21f4000 {
				compatible = "fsl,imx6q-uart\0fsl,imx21-uart";
				reg = <0x21f4000 0x4000>;
				interrupts = <0x00 0x1e 0x04>;
				clocks = <0x04 0xa0 0x04 0xa1>;
				clock-names = "ipg\0per";
				dmas = <0x0d 0x21 0x04 0x00 0x0d 0x22 0x04 0x00>;
				dma-names = "rx\0tx";
				status = "disabled";
			};

			i2c@21f8000 {
				#address-cells = <0x01>;
				#size-cells = <0x00>;
				compatible = "fsl,imx6q-i2c\0fsl,imx21-i2c";
				reg = <0x21f8000 0x4000>;
				interrupts = <0x00 0x23 0x04>;
				clocks = <0x04 0x74>;
				status = "disabled";
			};

			otp-ctrl@21bc000 {
				compatible = "fsl,imx6q-otp\0syscon";
				clocks = <0x04 0x80>;
				ocotp = <0x03>;
			};
		};

		ipu@2400000 {
			#address-cells = <0x01>;
			#size-cells = <0x00>;
			compatible = "fsl,imx6q-ipu";
			reg = <0x2400000 0x400000>;
			interrupts = <0x00 0x06 0x04 0x00 0x05 0x04>;
			clocks = <0x04 0x82 0x04 0x83 0x04 0x84 0x04 0x27 0x04 0x28 0x04 0x87 0x04 0x88>;
			clock-names = "bus\0di0\0di1\0di0_sel\0di1_sel\0ldb_di0\0ldb_di1";
			resets = <0x11 0x02>;
			bypass_reset = <0x00>;

			port@0 {
				reg = <0x00>;
				phandle = <0x46>;

				endpoint {
					remote-endpoint = <0x39>;
					phandle = <0x1c>;
				};
			};

			port@1 {
				reg = <0x01>;
				phandle = <0x47>;

				endpoint {
					remote-endpoint = <0x3a>;
					phandle = <0x21>;
				};
			};

			port@2 {
				#address-cells = <0x01>;
				#size-cells = <0x00>;
				reg = <0x02>;
				phandle = <0x48>;

				endpoint@0 {
					reg = <0x00>;
				};

				endpoint@1 {
					reg = <0x01>;
					remote-endpoint = <0x3b>;
					phandle = <0x0b>;
				};

				endpoint@2 {
					reg = <0x02>;
					remote-endpoint = <0x3c>;
					phandle = <0x36>;
				};

				endpoint@3 {
					reg = <0x03>;
					remote-endpoint = <0x3d>;
					phandle = <0x06>;
				};

				endpoint@4 {
					reg = <0x04>;
					remote-endpoint = <0x3e>;
					phandle = <0x08>;
				};
			};

			port@3 {
				#address-cells = <0x01>;
				#size-cells = <0x00>;
				reg = <0x03>;
				phandle = <0x49>;

				endpoint@0 {
					reg = <0x00>;
				};

				endpoint@1 {
					reg = <0x01>;
					remote-endpoint = <0x3f>;
					phandle = <0x0c>;
				};

				endpoint@2 {
					reg = <0x02>;
					remote-endpoint = <0x40>;
					phandle = <0x37>;
				};

				endpoint@3 {
					reg = <0x03>;
					remote-endpoint = <0x41>;
					phandle = <0x07>;
				};

				endpoint@4 {
					reg = <0x04>;
					remote-endpoint = <0x42>;
					phandle = <0x09>;
				};
			};
		};

		busfreq {
			compatible = "fsl,imx_busfreq";
			clocks = <0x04 0xab 0x04 0x06 0x04 0x0b 0x04 0x68 0x04 0xac 0x04 0x3a 0x04 0x12 0x04 0x3c 0x04 0x14 0x04 0x03 0x04 0x10a 0x04 0x16 0x04 0x08>;
			clock-names = "pll2_bus\0pll2_pfd2_396m\0pll2_198m\0arm\0pll3_usb_otg\0periph\0periph_pre\0periph_clk2\0periph_clk2_sel\0osc\0axi_alt_sel\0axi_sel\0pll3_pfd1_540m";
			interrupts = <0x00 0x6b 0x04 0x00 0x70 0x04>;
			interrupt-names = "irq_busfreq_0\0irq_busfreq_1";
			fsl,max_ddr_freq = <0x17d78400>;
		};

		sram@905000 {
			compatible = "mmio-sram";
			reg = <0x905000 0x1b000>;
			clocks = <0x04 0x8e>;
			phandle = <0x12>;
		};

		sram@918000 {
			compatible = "fsl,optee-lpm-sram";
			reg = <0x918000 0x8000>;
			overw_reg = <0x12 0x905000 0x13000>;
		};

		gpu@00130000 {
			compatible = "fsl,imx6dl-gpu\0fsl,imx6q-gpu";
			reg = <0x130000 0x4000 0x134000 0x4000 0x10000000 0x00 0x00 0x8000000>;
			reg-names = "iobase_3d\0iobase_2d\0phys_baseaddr\0contiguous_mem";
			interrupts = <0x00 0x09 0x04 0x00 0x0a 0x04>;
			interrupt-names = "irq_3d\0irq_2d";
			clocks = <0x04 0x8f 0x04 0x1b 0x04 0x79 0x04 0x7a 0x04 0x00>;
			clock-names = "gpu2d_axi_clk\0gpu3d_axi_clk\0gpu2d_clk\0gpu3d_clk\0gpu3d_shader_clk";
			resets = <0x11 0x00 0x11 0x03>;
			reset-names = "gpu3d\0gpu2d";
			power-domains = <0x0e>;
			status = "okay";
		};
	};

	cpus {
		#address-cells = <0x01>;
		#size-cells = <0x00>;

		cpu@0 {
			compatible = "arm,cortex-a9";
			device_type = "cpu";
			reg = <0x00>;
			next-level-cache = <0x43>;
			operating-points = <0xf32a0 0x1312d0 0xc15c0 0x11edd8 0x60ae0 0x118c30>;
			fsl,soc-operating-points = <0xf32a0 0x11edd8 0xc15c0 0x11edd8 0x60ae0 0x11edd8>;
			clock-latency = <0xee6c>;
			#cooling-cells = <0x02>;
			clocks = <0x04 0x68 0x04 0x06 0x04 0x10 0x04 0x11 0x04 0xaa 0x04 0xdf 0x04 0xe6 0x04 0xd8>;
			clock-names = "arm\0pll2_pfd2_396m\0step\0pll1_sw\0pll1_sys\0pll1\0pll1_bypass\0pll1_bypass_src";
			arm-supply = <0x44>;
			pu-supply = <0x16>;
			soc-supply = <0x45>;
		};

		cpu@1 {
			compatible = "arm,cortex-a9";
			device_type = "cpu";
			reg = <0x01>;
			next-level-cache = <0x43>;
			operating-points = <0xf32a0 0x1312d0 0xc15c0 0x11edd8 0x60ae0 0x118c30>;
			fsl,soc-operating-points = <0xf32a0 0x11edd8 0xc15c0 0x11edd8 0x60ae0 0x11edd8>;
			clock-latency = <0xee6c>;
			clocks = <0x04 0x68 0x04 0x06 0x04 0x10 0x04 0x11 0x04 0xaa>;
			clock-names = "arm\0pll2_pfd2_396m\0step\0pll1_sw\0pll1_sys";
			arm-supply = <0x44>;
			pu-supply = <0x16>;
			soc-supply = <0x45>;
		};
	};

	reserved-memory {
		#address-cells = <0x01>;
		#size-cells = <0x01>;
		ranges;

		linux,cma {
			compatible = "shared-dma-pool";
			reusable;
			size = <0x14000000>;
			linux,cma-default;
		};
	};

	capture-subsystem {
		compatible = "fsl,imx-capture-subsystem";
		ports = <0x46 0x47>;
	};

	display-subsystem {
		compatible = "fsl,imx-display-subsystem";
		ports = <0x48 0x49>;
	};

	memory {
		reg = <0x10000000 0x40000000>;
	};

	backlight {
		compatible = "pwm-backlight";
		pwms = <0x4a 0x00 0x4c4b40>;
		brightness-levels = <0x00 0x800 0x1000 0x2000 0x4000 0xffff>;
		num-interpolated-steps = <0x800>;
		default-brightness-level = <0xffff>;
		status = "okay";
	};

	lcd@0 {
		compatible = "fsl,lcd";
		ipu_id = <0x00>;
		disp_id = <0x00>;
		default_ifmt = "RGB24";
		pinctrl-names = "default";
		pinctrl-0 = <0x4b>;
		status = "okay";
	};

	fb@0 {
		compatible = "fsl,mxc_sdc_fb";
		disp_dev = "lcd";
		interface_pix_fmt = "RGB24";
		mode_str = "AUO";
		default_bpp = <0x10>;
		int_clk = <0x00>;
		late_init = <0x00>;
		status = "okay";
	};

	regulators {
		compatible = "simple-bus";
		#address-cells = <0x01>;
		#size-cells = <0x00>;

		regulator@0 {
			compatible = "regulator-fixed";
			reg = <0x00>;
			regulator-name = "vdd_3v3_reg";
			regulator-min-microvolt = <0x325aa0>;
			regulator-max-microvolt = <0x325aa0>;
			regulator-always-on;
			phandle = <0x2b>;
		};

		regulator@1 {
			compatible = "regulator-fixed";
			reg = <0x01>;
			regulator-name = "amp_supply_reg";
			regulator-min-microvolt = <0xd59f80>;
			regulator-max-microvolt = <0xd59f80>;
			regulator-always-on;
			phandle = <0x2c>;
		};
	};

	sound {
		compatible = "unu,imx-audio-tas5720";
		model = "imx-audio-tas5720";
		ssi-controller = <0x4c>;
		audio-codec = <0x4d>;
		audio-routing = "Output\0OUT";
		mux-int-port = <0x01>;
		mux-ext-port = <0x03>;
	};
};
